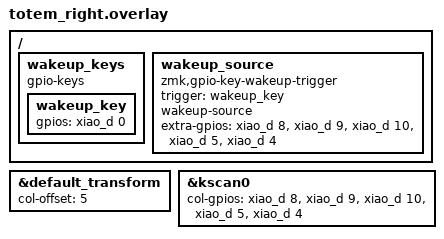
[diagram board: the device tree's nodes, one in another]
/*
 * Copyright (c) 2022 The ZMK Contributors
 *
 * SPDX-License-Identifier: MIT
 */

#include "totem.dtsi"

/ {
    wakeup_keys: wakeup_keys {
        compatible = "gpio-keys";
        wakeup_key: wakeup_key {
            gpios = <&xiao_d 0 GPIO_ACTIVE_HIGH>;
        };
    };

    wakeup_source: wakeup_source {
        compatible = "zmk,gpio-key-wakeup-trigger";
        trigger = <&wakeup_key>;
        wakeup-source;
        extra-gpios = <&xiao_d 8 GPIO_ACTIVE_HIGH>,
                      <&xiao_d 9 GPIO_ACTIVE_HIGH>,
                      <&xiao_d 10 GPIO_ACTIVE_HIGH>,
                      <&xiao_d 5 GPIO_ACTIVE_HIGH>,
                      <&xiao_d 4 GPIO_ACTIVE_HIGH>;
    };
};

&default_transform {
    col-offset = <5>;
};

&kscan0 {
    col-gpios
        = <&xiao_d 8 GPIO_ACTIVE_HIGH>
        , <&xiao_d 9 GPIO_ACTIVE_HIGH>
        , <&xiao_d 10 GPIO_ACTIVE_HIGH>
        , <&xiao_d 5 GPIO_ACTIVE_HIGH>
        , <&xiao_d 4 GPIO_ACTIVE_HIGH>
        ;
};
